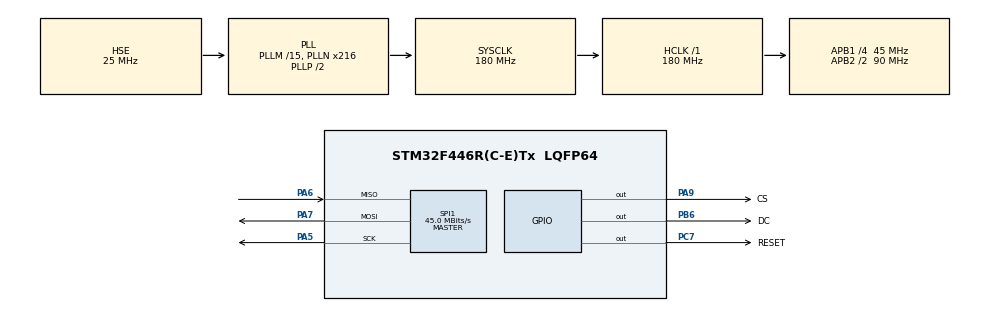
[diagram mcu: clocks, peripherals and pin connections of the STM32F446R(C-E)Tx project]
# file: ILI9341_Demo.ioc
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Dma.Request0=SPI1_TX
Dma.SPI1_TX.0.Direction=DMA_MEMORY_TO_PERIPH
Dma.SPI1_TX.0.FIFOMode=DMA_FIFOMODE_DISABLE
Dma.SPI1_TX.0.Instance=DMA2_Stream3
Dma.SPI1_TX.0.MemDataAlignment=DMA_MDATAALIGN_BYTE
Dma.SPI1_TX.0.MemInc=DMA_MINC_ENABLE
Dma.SPI1_TX.0.Mode=DMA_NORMAL
Dma.SPI1_TX.0.PeriphDataAlignment=DMA_PDATAALIGN_BYTE
Dma.SPI1_TX.0.PeriphInc=DMA_PINC_DISABLE
Dma.SPI1_TX.0.Priority=DMA_PRIORITY_LOW
Mcu.Family=STM32F4
Mcu.Name=STM32F446R(C-E)Tx
Mcu.Package=LQFP64
NVIC.DMA2_Stream3_IRQn=true\:0\:0\:false\:false\:true\:false\:true\:true
NVIC.PriorityGroup=NVIC_PRIORITYGROUP_4
NVIC.SPI1_IRQn=true\:0\:0\:false\:false\:true\:true\:true\:true
PA13.Mode=Serial_Wire
PA13.Signal=SYS_JTMS-SWDIO
PA14.Mode=Serial_Wire
PA14.Signal=SYS_JTCK-SWCLK
PA5.Mode=Full_Duplex_Master
PA5.Signal=SPI1_SCK
PA6.Mode=Full_Duplex_Master
PA6.Signal=SPI1_MISO
PA7.Mode=Full_Duplex_Master
PA7.Signal=SPI1_MOSI
PA9.GPIO_Label=CS
PA9.Signal=GPIO_Output
PB6.GPIO_Label=DC
PB6.Signal=GPIO_Output
PC7.GPIO_Label=RESET
PC7.Signal=GPIO_Output
PH0-OSC_IN.Mode=HSE-External-Oscillator
PH0-OSC_IN.Signal=RCC_OSC_IN
PH1-OSC_OUT.Mode=HSE-External-Oscillator
PH1-OSC_OUT.Signal=RCC_OSC_OUT
ProjectManager.HeapSize=0x200
ProjectManager.StackSize=0x400
ProjectManager.TargetToolchain=CMake
RCC.AHBFreq_Value=180000000
RCC.APB1CLKDivider=RCC_HCLK_DIV4
RCC.APB1Freq_Value=45000000
RCC.APB1TimFreq_Value=90000000
RCC.APB2CLKDivider=RCC_HCLK_DIV2
RCC.APB2Freq_Value=90000000
RCC.APB2TimFreq_Value=180000000
RCC.CortexFreq_Value=180000000
RCC.HCLKFreq_Value=180000000
RCC.PLLM=15
RCC.PLLN=216
RCC.PLLSourceVirtual=RCC_PLLSOURCE_HSE
RCC.SYSCLKFreq_VALUE=180000000
RCC.SYSCLKSource=RCC_SYSCLKSOURCE_PLLCLK
RCC.USBFreq_Value=180000000
RCC.VCOOutputFreq_Value=360000000
SPI1.CalculateBaudRate=45.0 MBits/s
SPI1.Direction=SPI_DIRECTION_2LINES
SPI1.Mode=SPI_MODE_MASTER
SPI1.VirtualType=VM_MASTER
board=custom

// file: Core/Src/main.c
/* USER CODE BEGIN Header */
/**
  ******************************************************************************
  * @file           : main.c
  * @brief          : Main program body
  ******************************************************************************
  * @attention
  *
  * Copyright (c) 2025 STMicroelectronics.
  * All rights reserved.
  *
  * This software is licensed under terms that can be found in the LICENSE file
  * in the root directory of this software component.
  * If no LICENSE file comes with this software, it is provided AS-IS.
  *
  ******************************************************************************
  */
/* USER CODE END Header */
#include "main.h"

/* USER CODE BEGIN Includes */
#include "ILI9341.h"
#include "lvgl.h"
#include "LCDController.h"

/* USER CODE END Includes */

SPI_HandleTypeDef hspi1;
DMA_HandleTypeDef hdma_spi1_tx;

void SystemClock_Config(void);
static void MX_GPIO_Init(void);
static void MX_DMA_Init(void);
static void MX_SPI1_Init(void);

int main(void)
{

  /* MCU Configuration--------------------------------------------------------*/

  /* Reset of all peripherals, Initializes the Flash interface and the Systick. */
  HAL_Init();

  /* Configure the system clock */
  SystemClock_Config();

  /* Initialize all configured peripherals */
  MX_GPIO_Init();
  MX_DMA_Init();
  MX_SPI1_Init();
  /* USER CODE BEGIN 2 */
  lv_init();
  lv_port_disp_init();

  /* Change Active Screen's background color */
lv_obj_set_style_bg_color(lv_screen_active(), lv_color_hex(0x003a57), LV_PART_MAIN);
lv_obj_set_style_text_color(lv_screen_active(), lv_color_hex(0xffffff), LV_PART_MAIN);

/* Create a spinner */
lv_obj_t * spinner = lv_spinner_create(lv_screen_active());
lv_obj_set_size(spinner, 64, 64);
lv_obj_align(spinner, LV_ALIGN_BOTTOM_MID, 0, 0);

  /* USER CODE END 2 */

  /* Infinite loop */
  while (1)
  {

    /* USER CODE BEGIN 3 */
	  lv_timer_handler();
	  HAL_Delay(5);

  }
  /* USER CODE END 3 */
}

void SystemClock_Config(void)
{
  RCC_OscInitTypeDef RCC_OscInitStruct = {0};
  RCC_ClkInitTypeDef RCC_ClkInitStruct = {0};

  /** Configure the main internal regulator output voltage
  */
  __HAL_RCC_PWR_CLK_ENABLE();
  __HAL_PWR_VOLTAGESCALING_CONFIG(PWR_REGULATOR_VOLTAGE_SCALE1);

  /** Initializes the RCC Oscillators according to the specified parameters
  * in the RCC_OscInitTypeDef structure.
  */
  RCC_OscInitStruct.OscillatorType = RCC_OSCILLATORTYPE_HSE;
  RCC_OscInitStruct.HSEState = RCC_HSE_ON;
  RCC_OscInitStruct.PLL.PLLState = RCC_PLL_ON;
  RCC_OscInitStruct.PLL.PLLSource = RCC_PLLSOURCE_HSE;
  RCC_OscInitStruct.PLL.PLLM = 15;
  RCC_OscInitStruct.PLL.PLLN = 216;
  RCC_OscInitStruct.PLL.PLLP = RCC_PLLP_DIV2;
  RCC_OscInitStruct.PLL.PLLQ = 2;
  RCC_OscInitStruct.PLL.PLLR = 2;
  if (HAL_RCC_OscConfig(&RCC_OscInitStruct) != HAL_OK)
  {
    Error_Handler();
  }

  /** Activate the Over-Drive mode
  */
  if (HAL_PWREx_EnableOverDrive() != HAL_OK)
  {
    Error_Handler();
  }

  /** Initializes the CPU, AHB and APB buses clocks
  */
  RCC_ClkInitStruct.ClockType = RCC_CLOCKTYPE_HCLK|RCC_CLOCKTYPE_SYSCLK
                              |RCC_CLOCKTYPE_PCLK1|RCC_CLOCKTYPE_PCLK2;
  RCC_ClkInitStruct.SYSCLKSource = RCC_SYSCLKSOURCE_PLLCLK;
  RCC_ClkInitStruct.AHBCLKDivider = RCC_SYSCLK_DIV1;
  RCC_ClkInitStruct.APB1CLKDivider = RCC_HCLK_DIV4;
  RCC_ClkInitStruct.APB2CLKDivider = RCC_HCLK_DIV2;

  if (HAL_RCC_ClockConfig(&RCC_ClkInitStruct, FLASH_LATENCY_5) != HAL_OK)
  {
    Error_Handler();
  }
}

static void MX_SPI1_Init(void)
{

  /* SPI1 parameter configuration*/
  hspi1.Instance = SPI1;
  hspi1.Init.Mode = SPI_MODE_MASTER;
  hspi1.Init.Direction = SPI_DIRECTION_2LINES;
  hspi1.Init.DataSize = SPI_DATASIZE_8BIT;
  hspi1.Init.CLKPolarity = SPI_POLARITY_LOW;
  hspi1.Init.CLKPhase = SPI_PHASE_1EDGE;
  hspi1.Init.NSS = SPI_NSS_SOFT;
  hspi1.Init.BaudRatePrescaler = SPI_BAUDRATEPRESCALER_2;
  hspi1.Init.FirstBit = SPI_FIRSTBIT_MSB;
  hspi1.Init.TIMode = SPI_TIMODE_DISABLE;
  hspi1.Init.CRCCalculation = SPI_CRCCALCULATION_DISABLE;
  hspi1.Init.CRCPolynomial = 10;
  if (HAL_SPI_Init(&hspi1) != HAL_OK)
  {
    Error_Handler();
  }

}

static void MX_DMA_Init(void)
{

  /* DMA controller clock enable */
  __HAL_RCC_DMA2_CLK_ENABLE();

  /* DMA interrupt init */
  /* DMA2_Stream3_IRQn interrupt configuration */
  HAL_NVIC_SetPriority(DMA2_Stream3_IRQn, 0, 0);
  HAL_NVIC_EnableIRQ(DMA2_Stream3_IRQn);

}

static void MX_GPIO_Init(void)
{
  GPIO_InitTypeDef GPIO_InitStruct = {0};

  /* GPIO Ports Clock Enable */
  __HAL_RCC_GPIOH_CLK_ENABLE();
  __HAL_RCC_GPIOA_CLK_ENABLE();
  __HAL_RCC_GPIOC_CLK_ENABLE();
  __HAL_RCC_GPIOB_CLK_ENABLE();

  /*Configure GPIO pin Output Level */
  HAL_GPIO_WritePin(RESET_GPIO_Port, RESET_Pin, GPIO_PIN_RESET);

  /*Configure GPIO pin Output Level */
  HAL_GPIO_WritePin(CS_GPIO_Port, CS_Pin, GPIO_PIN_RESET);

  /*Configure GPIO pin Output Level */
  HAL_GPIO_WritePin(DC_GPIO_Port, DC_Pin, GPIO_PIN_RESET);

  /*Configure GPIO pin : RESET_Pin */
  GPIO_InitStruct.Pin = RESET_Pin;
  GPIO_InitStruct.Mode = GPIO_MODE_OUTPUT_PP;
  GPIO_InitStruct.Pull = GPIO_NOPULL;
  GPIO_InitStruct.Speed = GPIO_SPEED_FREQ_LOW;
  HAL_GPIO_Init(RESET_GPIO_Port, &GPIO_InitStruct);

  /*Configure GPIO pin : CS_Pin */
  GPIO_InitStruct.Pin = CS_Pin;
  GPIO_InitStruct.Mode = GPIO_MODE_OUTPUT_PP;
  GPIO_InitStruct.Pull = GPIO_NOPULL;
  GPIO_InitStruct.Speed = GPIO_SPEED_FREQ_LOW;
  HAL_GPIO_Init(CS_GPIO_Port, &GPIO_InitStruct);

  /*Configure GPIO pin : DC_Pin */
  GPIO_InitStruct.Pin = DC_Pin;
  GPIO_InitStruct.Mode = GPIO_MODE_OUTPUT_PP;
  GPIO_InitStruct.Pull = GPIO_NOPULL;
  GPIO_InitStruct.Speed = GPIO_SPEED_FREQ_LOW;
  HAL_GPIO_Init(DC_GPIO_Port, &GPIO_InitStruct);

}

void Error_Handler(void)
{
  __disable_irq();
  while (1)
  {
  }
}
